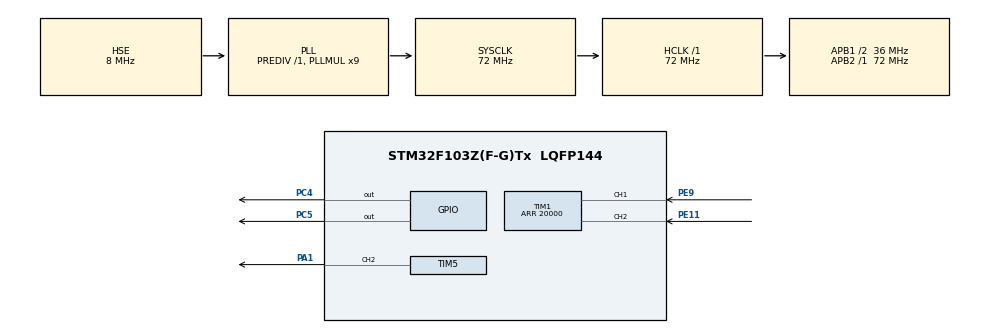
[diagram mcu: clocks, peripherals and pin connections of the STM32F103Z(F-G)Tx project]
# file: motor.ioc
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Mcu.Family=STM32F1
Mcu.Name=STM32F103Z(F-G)Tx
Mcu.Package=LQFP144
NVIC.PriorityGroup=NVIC_PRIORITYGROUP_4
NVIC.TIM1_UP_TIM10_IRQn=true\:0\:0\:true\:false\:true\:true\:true
NVIC.TIM6_IRQn=true\:1\:0\:true\:false\:true\:true\:true
OSC_IN.Mode=HSE-External-Oscillator
OSC_IN.Signal=RCC_OSC_IN
OSC_OUT.Mode=HSE-External-Oscillator
OSC_OUT.Signal=RCC_OSC_OUT
PA1.Signal=S_TIM5_CH2
PA13.Mode=Serial_Wire
PA13.Signal=SYS_JTMS-SWDIO
PA14.Mode=Serial_Wire
PA14.Signal=SYS_JTCK-SWCLK
PC4.Signal=GPIO_Output
PC5.Signal=GPIO_Output
PE11.Signal=S_TIM1_CH2
PE9.Signal=S_TIM1_CH1
ProjectManager.HeapSize=0x200
ProjectManager.StackSize=0x400
ProjectManager.TargetToolchain=MDK-ARM V5
RCC.AHBFreq_Value=72000000
RCC.APB1CLKDivider=RCC_HCLK_DIV2
RCC.APB1Freq_Value=36000000
RCC.APB1TimFreq_Value=72000000
RCC.APB2Freq_Value=72000000
RCC.APB2TimFreq_Value=72000000
RCC.HCLKFreq_Value=72000000
RCC.PLLMUL=RCC_PLL_MUL9
RCC.PLLSourceVirtual=RCC_PLLSOURCE_HSE
RCC.SYSCLKFreq_VALUE=72000000
RCC.SYSCLKSource=RCC_SYSCLKSOURCE_PLLCLK
RCC.USBFreq_Value=72000000
SH.S_TIM1_CH1.0=TIM1_CH1,Encoder_Interface
SH.S_TIM1_CH2.0=TIM1_CH2,Encoder_Interface
SH.S_TIM5_CH2.0=TIM5_CH2,PWM Generation2 CH2
TIM1.EncoderMode=TIM_ENCODERMODE_TI12
TIM1.Period=20000
TIM5.AutoReloadPreload=TIM_AUTORELOAD_PRELOAD_ENABLE
TIM5.Channel-PWM\ Generation2\ CH2=TIM_CHANNEL_2
TIM5.Period=10000
TIM5.Prescaler=72-1
TIM6.Period=10000
TIM6.Prescaler=72-1
VP_TIM6_VS_ClockSourceINT.Mode=Enable_Timer
board=custom

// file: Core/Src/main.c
/* USER CODE BEGIN Header */
/**
  ******************************************************************************
  * @file           : main.c
  * @brief          : Main program body
  ******************************************************************************
  * @attention
  *
  * <h2><center>&copy; Copyright (c) 2021 STMicroelectronics.
  * All rights reserved.</center></h2>
  *
  * This software component is licensed by ST under BSD 3-Clause license,
  * the "License"; You may not use this file except in compliance with the
  * License. You may obtain a copy of the License at:
  *                        opensource.org/licenses/BSD-3-Clause
  *
  ******************************************************************************
  */
/* USER CODE END Header */
#include "main.h"
#include "tim.h"
#include "gpio.h"

/* USER CODE BEGIN Includes */
#include "Motor.h"
/* USER CODE END Includes */

/* USER CODE BEGIN PTD */
float speed = 0;
/* USER CODE END PTD */

void SystemClock_Config(void);

int main(void)
{

  /* MCU Configuration--------------------------------------------------------*/

  /* Reset of all peripherals, Initializes the Flash interface and the Systick. */
  HAL_Init();

  /* Configure the system clock */
  SystemClock_Config();

  /* Initialize all configured peripherals */
  MX_GPIO_Init();
  MX_TIM1_Init();
  MX_TIM6_Init();
  MX_TIM5_Init();
  /* USER CODE BEGIN 2 */
	Motor_Init();
  /* USER CODE END 2 */

  /* Infinite loop */
  /* USER CODE BEGIN WHILE */
	motor.targetSpeed = speed;
  while (1)
  {
    /* USER CODE END WHILE */

  }
}

void SystemClock_Config(void)
{
  RCC_OscInitTypeDef RCC_OscInitStruct = {0};
  RCC_ClkInitTypeDef RCC_ClkInitStruct = {0};

  /** Initializes the RCC Oscillators according to the specified parameters
  * in the RCC_OscInitTypeDef structure.
  */
  RCC_OscInitStruct.OscillatorType = RCC_OSCILLATORTYPE_HSE;
  RCC_OscInitStruct.HSEState = RCC_HSE_ON;
  RCC_OscInitStruct.HSEPredivValue = RCC_HSE_PREDIV_DIV1;
  RCC_OscInitStruct.HSIState = RCC_HSI_ON;
  RCC_OscInitStruct.PLL.PLLState = RCC_PLL_ON;
  RCC_OscInitStruct.PLL.PLLSource = RCC_PLLSOURCE_HSE;
  RCC_OscInitStruct.PLL.PLLMUL = RCC_PLL_MUL9;
  if (HAL_RCC_OscConfig(&RCC_OscInitStruct) != HAL_OK)
  {
    Error_Handler();
  }
  /** Initializes the CPU, AHB and APB buses clocks
  */
  RCC_ClkInitStruct.ClockType = RCC_CLOCKTYPE_HCLK|RCC_CLOCKTYPE_SYSCLK
                              |RCC_CLOCKTYPE_PCLK1|RCC_CLOCKTYPE_PCLK2;
  RCC_ClkInitStruct.SYSCLKSource = RCC_SYSCLKSOURCE_PLLCLK;
  RCC_ClkInitStruct.AHBCLKDivider = RCC_SYSCLK_DIV1;
  RCC_ClkInitStruct.APB1CLKDivider = RCC_HCLK_DIV2;
  RCC_ClkInitStruct.APB2CLKDivider = RCC_HCLK_DIV1;

  if (HAL_RCC_ClockConfig(&RCC_ClkInitStruct, FLASH_LATENCY_2) != HAL_OK)
  {
    Error_Handler();
  }
}

void Error_Handler(void)
{
  __disable_irq();
  while (1)
  {
  }
}

/************************ (C) COPYRIGHT STMicroelectronics *****END OF FILE****/
